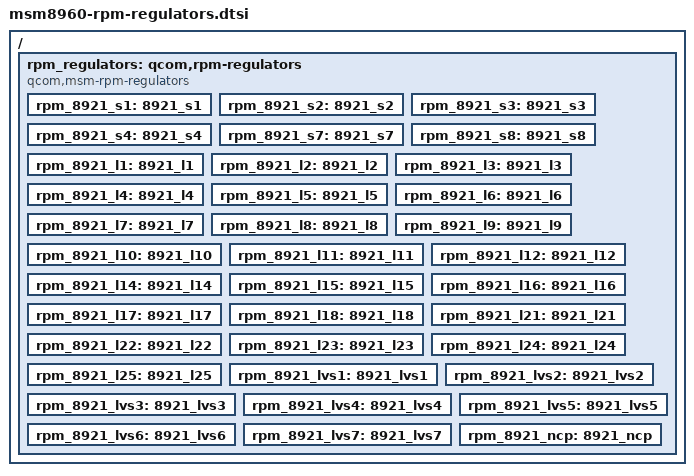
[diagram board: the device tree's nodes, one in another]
/* Copyright (c) 2012, Motorola Mobility LLC. All rights reserved.
 *
 * This program is free software; you can redistribute it and/or modify
 * it under the terms of the GNU General Public License version 2 and
 * only version 2 as published by the Free Software Foundation.
 *
 * This program is distributed in the hope that it will be useful,
 * but WITHOUT ANY WARRANTY; without even the implied warranty of
 * MERCHANTABILITY or FITNESS FOR A PARTICULAR PURPOSE.  See the
 * GNU General Public License for more details.
 */

/ {
	rpm_regulators: qcom,rpm-regulators {
		compatible = "qcom,msm-rpm-regulators";

		/* RPM SMPS */
		rpm_8921_s1: 8921_s1 {
			status = "okay";
		};
		rpm_8921_s2: 8921_s2 {
			status = "okay";
		};
		rpm_8921_s3: 8921_s3 {
			status = "okay";
		};
		rpm_8921_s4: 8921_s4 {
			status = "okay";
		};
		rpm_8921_s7: 8921_s7 {
			status = "okay";
		};
		rpm_8921_s8: 8921_s8 {
			status = "okay";
		};

		/* RPM LDOs */
		rpm_8921_l1: 8921_l1 {
			status = "okay";
		};
		rpm_8921_l2: 8921_l2 {
			status = "okay";
		};
		rpm_8921_l3: 8921_l3 {
			status = "okay";
		};
		rpm_8921_l4: 8921_l4 {
			status = "okay";
		};
		rpm_8921_l5: 8921_l5 {
			status = "okay";
		};
		rpm_8921_l6: 8921_l6 {
			status = "okay";
		};
		rpm_8921_l7: 8921_l7 {
			status = "okay";
		};
		rpm_8921_l8: 8921_l8 {
			status = "okay";
		};
		rpm_8921_l9: 8921_l9 {
			status = "okay";
		};
		rpm_8921_l10: 8921_l10 {
			status = "okay";
		};
		rpm_8921_l11: 8921_l11 {
			status = "okay";
		};
		rpm_8921_l12: 8921_l12 {
			status = "okay";
		};
		rpm_8921_l14: 8921_l14 {
			status = "okay";
		};
		rpm_8921_l15: 8921_l15 {
			status = "okay";
		};
		rpm_8921_l16: 8921_l16 {
			status = "okay";
		};
		rpm_8921_l17: 8921_l17 {
			status = "okay";
		};
		rpm_8921_l18: 8921_l18 {
			status = "okay";
		};
		rpm_8921_l21: 8921_l21 {
			status = "okay";
		};
		rpm_8921_l22: 8921_l22 {
			status = "okay";
		};
		rpm_8921_l23: 8921_l23 {
			status = "okay";
		};
		rpm_8921_l24: 8921_l24 {
			status = "okay";
		};
		rpm_8921_l25: 8921_l25 {
			status = "okay";
		};

		/* RPM LVS */
		rpm_8921_lvs1: 8921_lvs1 {
			status = "okay";
		};
		rpm_8921_lvs2: 8921_lvs2 {
			status = "okay";
		};
		rpm_8921_lvs3: 8921_lvs3 {
			status = "okay";
		};
		rpm_8921_lvs4: 8921_lvs4 {
			status = "okay";
		};
		rpm_8921_lvs5: 8921_lvs5 {
			status = "okay";
		};
		rpm_8921_lvs6: 8921_lvs6 {
			status = "okay";
		};
		rpm_8921_lvs7: 8921_lvs7 {
			status = "okay";
		};

		/* RPM NCP */
		rpm_8921_ncp: 8921_ncp {
			status = "okay";
		};
	};
};
